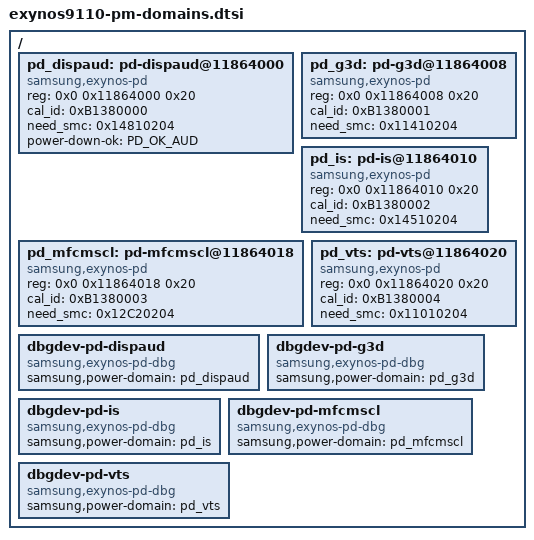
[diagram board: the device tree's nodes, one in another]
/*
 * SAMSUNG EXYNOS9810 SoC PM Domains device tree source
 *
 * Copyright (c) 2017 Samsung Electronics Co., Ltd.
 *		http://www.samsung.com
 *
 * SAMSUNG EXYNOS9810 SoC PM domains device nodes are listed in this file.
 * EXYNOS9810 based board files can include this file and provide
 * values for board specfic bindings.
 *
 * This program is free software; you can redistribute it and/or modify
 * it under the terms of the GNU General Public License version 2 as
 * published by the Free Software Foundation.
 */
#include <dt-bindings/power/exynos-power.h>

/ {
	pd_dispaud: pd-dispaud@11864000 {
		compatible = "samsung,exynos-pd";
		reg = <0x0 0x11864000 0x20>;
		cal_id = <0xB1380000>;
		need_smc = <0x14810204>;
		status = "okay";
		power-down-ok = <PD_OK_AUD>;
	};

	pd_g3d: pd-g3d@11864008 {
		compatible = "samsung,exynos-pd";
		reg = <0x0 0x11864008 0x20>;
		cal_id = <0xB1380001>;
		need_smc = <0x11410204>;
		status = "okay";
	};

	pd_is: pd-is@11864010 {
		compatible = "samsung,exynos-pd";
		reg = <0x0 0x11864010 0x20>;
		cal_id = <0xB1380002>;
		need_smc = <0x14510204>;
		status = "okay";
	};

	pd_mfcmscl: pd-mfcmscl@11864018 {
		compatible = "samsung,exynos-pd";
		reg = <0x0 0x11864018 0x20>;
		cal_id = <0xB1380003>;
		need_smc = <0x12C20204>;
		status = "okay";
	};

	pd_vts: pd-vts@11864020 {
		compatible = "samsung,exynos-pd";
		reg = <0x0 0x11864020 0x20>;
		cal_id = <0xB1380004>;
		need_smc = <0x11010204>;
		status = "okay";
	};

	dbgdev-pd-dispaud {
		compatible = "samsung,exynos-pd-dbg";
		samsung,power-domain = <&pd_dispaud>;
	};

	dbgdev-pd-g3d {
		compatible = "samsung,exynos-pd-dbg";
		samsung,power-domain = <&pd_g3d>;
	};

	dbgdev-pd-is {
		compatible = "samsung,exynos-pd-dbg";
		samsung,power-domain = <&pd_is>;
	};

	dbgdev-pd-mfcmscl {
		compatible = "samsung,exynos-pd-dbg";
		samsung,power-domain = <&pd_mfcmscl>;
	};

	dbgdev-pd-vts {
		compatible = "samsung,exynos-pd-dbg";
		samsung,power-domain = <&pd_vts>;
	};

};
